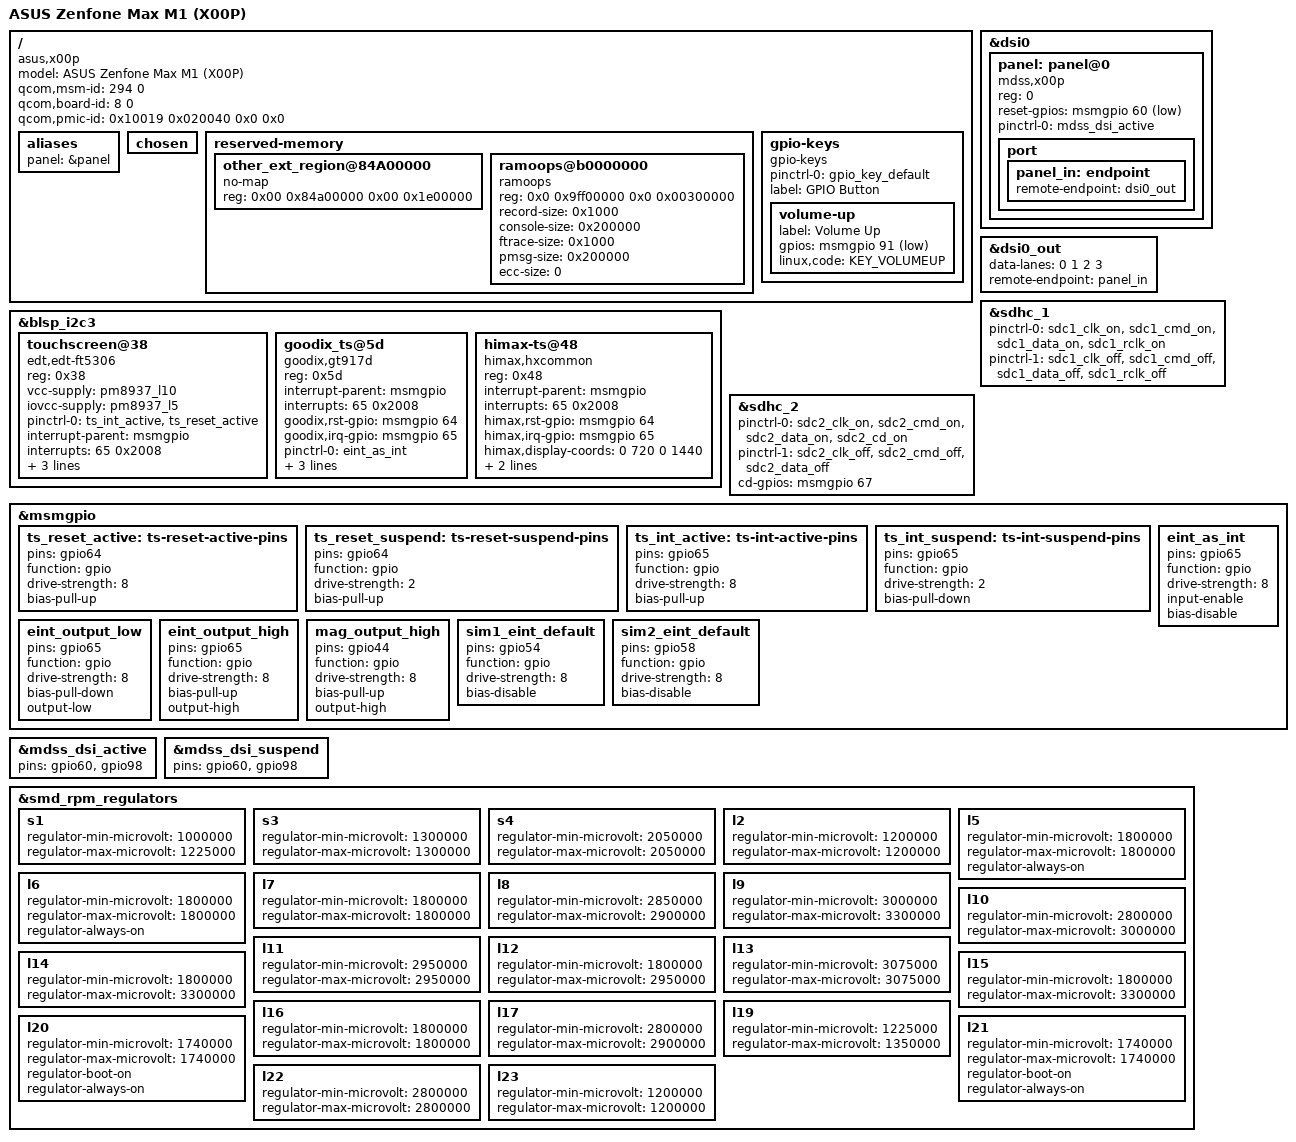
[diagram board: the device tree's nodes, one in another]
/dts-v1/;

#include "msm8940-pm8937.dtsi"
#include <dt-bindings/leds/common.h>
#include <dt-bindings/gpio/gpio.h>

/ {
	model = "ASUS Zenfone Max M1 (X00P)";
	compatible = "asus,x00p", "qcom,msm8937";

	qcom,msm-id = <294 0>;
	qcom,board-id= <8 0>;
	qcom,pmic-id = <0x10019 0x020040 0x0 0x0>;

	aliases {
		panel = &panel;
	};

	chosen {};

	reserved-memory {
		/delete-node/other_ext_region@85b00000;

		other_ext_region@84A00000 {
			no-map;
			reg = <0x00 0x84a00000 0x00 0x1e00000>;
		};

		ramoops@b0000000 {
			compatible = "ramoops";
			reg = <0x0 0x9ff00000 0x0 0x00300000>;
			record-size = <0x1000>;
			console-size = <0x200000>;
			ftrace-size = <0x1000>;
			pmsg-size = <0x200000>;
			ecc-size = <0>;
		};
	};

	gpio-keys {
		compatible = "gpio-keys";

		pinctrl-names = "default";
		pinctrl-0 = <&gpio_key_default>;

		label = "GPIO Button";

		volume-up {
			label = "Volume Up";
			gpios = <&msmgpio 91 GPIO_ACTIVE_LOW>;
			linux,code = <KEY_VOLUMEUP>;
		};
	};
};

&blsp_i2c3 {
	status = "okay";

	touchscreen@38 {
		compatible = "edt,edt-ft5306", "edt,edt-ft5x06";
		reg = <0x38>;
		vcc-supply = <&pm8937_l10>;
		iovcc-supply = <&pm8937_l5>;
		pinctrl-names = "default";
		pinctrl-0 = <&ts_int_active &ts_reset_active>;
		interrupt-parent = <&msmgpio>;
		interrupts = <65 0x2008>;
		reset-gpios = <&msmgpio 64 GPIO_ACTIVE_LOW>;
		touchscreen-size-x = <720>;
		touchscreen-size-y = <1280>;
	};
	
	goodix_ts@5d {
		compatible = "goodix,gt917d";
		reg = <0x5d>;
		interrupt-parent = <&msmgpio>;
		interrupts = <65 0x2008>;
		goodix,rst-gpio = <&msmgpio 64 0x00>;
		goodix,irq-gpio = <&msmgpio 65 0x2008>;
		pinctrl-names = "eint_as_int","eint_output_low", "eint_output_high", "mag_output_high";
		pinctrl-0 = <&eint_as_int>;
		pinctrl-1 = <&eint_output_low>;
		pinctrl-2 = <&eint_output_high>;
		pinctrl-3 = <&mag_output_high>;
	};
	
	himax-ts@48 {
		compatible = "himax,hxcommon";
		reg = <0x48>;
		interrupt-parent = <&msmgpio>;
		interrupts = <65 0x2008>;
		himax,rst-gpio = <&msmgpio 64 0x00>;
		himax,irq-gpio = <&msmgpio 65 0x2008>;
		himax,display-coords = <0 720 0 1440 >;
		himax,panel-coords = <0 720 0 1440>;
		pinctrl-names = "mag_output_high";
		pinctrl-0 = <&mag_output_high>;
	};
};

&dsi0 {
	panel: panel@0 {
		compatible = "mdss,x00p";
		reg = <0>;
		
		reset-gpios = <&msmgpio 60 GPIO_ACTIVE_LOW>;
		
		pinctrl-names = "default";
		pinctrl-0 = <&mdss_dsi_active>;

		port {
			panel_in: endpoint {
				remote-endpoint = <&dsi0_out>;
			};
		};
	};
};

&dsi0_out {
	data-lanes = <0 1 2 3>;
	remote-endpoint = <&panel_in>;
};

&sdhc_1 {
	status = "okay";

	pinctrl-names = "default", "sleep";
	pinctrl-0 = <&sdc1_clk_on &sdc1_cmd_on &sdc1_data_on &sdc1_rclk_on>;
	pinctrl-1 = <&sdc1_clk_off &sdc1_cmd_off &sdc1_data_off &sdc1_rclk_off>;
};

&sdhc_2 {
	status = "okay";

	pinctrl-names = "default", "sleep";
	pinctrl-0 = <&sdc2_clk_on &sdc2_cmd_on &sdc2_data_on &sdc2_cd_on>;
	pinctrl-1 = <&sdc2_clk_off &sdc2_cmd_off &sdc2_data_off>;

	cd-gpios = <&msmgpio 67 GPIO_ACTIVE_HIGH>;
};

&msmgpio {
	ts_reset_active: ts-reset-active-pins {
		pins = "gpio64";
		function = "gpio";
		drive-strength = <8>;
		bias-pull-up;
	};

	ts_reset_suspend: ts-reset-suspend-pins {
		pins = "gpio64";
		function = "gpio";
		drive-strength = <2>;
		bias-pull-up;
	};

	ts_int_active: ts-int-active-pins {
		pins = "gpio65";
		function = "gpio";
		drive-strength = <8>;
		bias-pull-up;
	};

	ts_int_suspend: ts-int-suspend-pins {
		pins = "gpio65";
		function = "gpio";
		drive-strength = <2>;
		bias-pull-down;
	};
	
	eint_as_int: eint_as_int {
		pins = "gpio65";
		function = "gpio";
		drive-strength = <8>;
		input-enable; 
		bias-disable;
	};
	
	eint_output_low: eint_output_low {
		pins = "gpio65";
		function = "gpio";
		drive-strength = <8>;
		bias-pull-down;
		output-low;
	};
	
	eint_output_low: eint_output_low {
		pins = "gpio65";
		function = "gpio";
		drive-strength = <8>;
		bias-pull-down;
		output-low;
	};

	eint_output_high: eint_output_high {
		pins = "gpio65";
		function = "gpio";
		drive-strength = <8>;
		bias-pull-up;
		output-high;
	};
	
	mag_output_high: mag_output_high {
		pins = "gpio44";
		function = "gpio";
		drive-strength = <8>;
		bias-pull-up;
		output-high;
	};

	sim1_eint_default: sim1_eint_default {
		pins = "gpio54";
		function = "gpio";
		drive-strength = <8>;
		bias-disable;
	};

	sim2_eint_default: sim2_eint_default {
		pins = "gpio58";
		function = "gpio";
		drive-strength = <8>;
		bias-disable;
	};
};

&mdss_dsi_active {
	pins = "gpio60", "gpio98";
};

&mdss_dsi_suspend {
	pins = "gpio60", "gpio98";
};

&smd_rpm_regulators {
	s1 {
		regulator-min-microvolt = <1000000>;
		regulator-max-microvolt = <1225000>;
	};
	s3 {
		regulator-min-microvolt = <1300000>;
		regulator-max-microvolt = <1300000>;
	};
	s4 {
		regulator-min-microvolt = <2050000>;
		regulator-max-microvolt = <2050000>;
	};
	l2 {
		regulator-min-microvolt = <1200000>;
		regulator-max-microvolt = <1200000>;
	};
	l5 {
		regulator-min-microvolt = <1800000>;
		regulator-max-microvolt = <1800000>;
		regulator-always-on;
	};
	l6 {
		regulator-min-microvolt = <1800000>;
		regulator-max-microvolt = <1800000>;
		regulator-always-on;
	};
	l7 {
		regulator-min-microvolt = <1800000>;
		regulator-max-microvolt = <1800000>;
	};
	l8 {
		regulator-min-microvolt = <2850000>;
		regulator-max-microvolt = <2900000>;
	};
	l9 {
		regulator-min-microvolt = <3000000>;
		regulator-max-microvolt = <3300000>;
	};
	l10 {
		regulator-min-microvolt = <2800000>;
		regulator-max-microvolt = <3000000>;
	};
	l11 {
		regulator-min-microvolt = <2950000>;
		regulator-max-microvolt = <2950000>;
	};
	l12 {
		regulator-min-microvolt = <1800000>;
		regulator-max-microvolt = <2950000>;
	};
	l13 {
		regulator-min-microvolt = <3075000>;
		regulator-max-microvolt = <3075000>;
	};
	l14 {
		regulator-min-microvolt = <1800000>;
		regulator-max-microvolt = <3300000>;
	};
	l15 {
		regulator-min-microvolt = <1800000>;
		regulator-max-microvolt = <3300000>;
	};
	l16 {
		regulator-min-microvolt = <1800000>;
		regulator-max-microvolt = <1800000>;
	};
	l17 {
		regulator-min-microvolt = <2800000>;
		regulator-max-microvolt = <2900000>;
	};
	l19 {
		regulator-min-microvolt = <1225000>;
		regulator-max-microvolt = <1350000>;
	};
	l20 {
		regulator-min-microvolt = <1740000>;
		regulator-max-microvolt = <1740000>;
		regulator-boot-on;
		regulator-always-on;
	};
	l21 {
		regulator-min-microvolt = <1740000>;
		regulator-max-microvolt = <1740000>;
		regulator-boot-on;
		regulator-always-on;
	};
	l22 {
		regulator-min-microvolt = <2800000>;
		regulator-max-microvolt = <2800000>;
	};
	l23 {
		regulator-min-microvolt = <1200000>;
		regulator-max-microvolt = <1200000>;
	};
};
